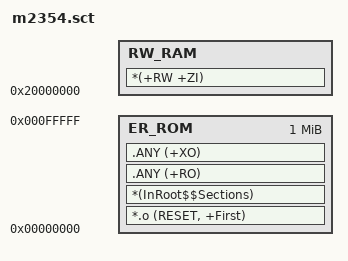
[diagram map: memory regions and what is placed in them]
#! armclang -E --target=arm-arm-none-eabi -mcpu=cortex-m23 -xc

/*----------------------------------------------------------------------------
  Scatter Region definition
 *----------------------------------------------------------------------------*/
LR_ROM 0 0x100000 {
    ER_ROM 0 0x100000 {
        *.o (RESET, +First)
        *(InRoot$$Sections)
        .ANY (+RO)
        .ANY (+XO)
    }

    RW_RAM 0x20000000 ALIGN 8 {
        *(+RW +ZI)
    }
}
